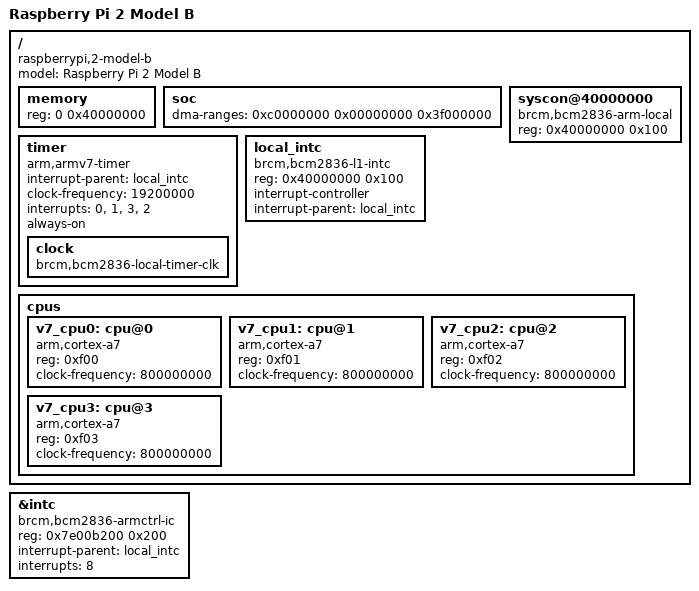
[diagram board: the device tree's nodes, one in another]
/dts-v1/;
#include "bcm2835-rpi.dtsi"

/ {
	compatible = "raspberrypi,2-model-b", "brcm,bcm2836";
	model = "Raspberry Pi 2 Model B";

	memory {
		reg = <0 0x40000000>;
	};

	soc {
		ranges = <0x7e000000 0x3f000000 0x1000000>,
			 <0x40000000 0x40000000 0x00001000>;
		dma-ranges = <0xc0000000 0x00000000 0x3f000000>;

		/delete-node/ timer@7e003000;
		/delete-node/ arm-pmu;
	};

	syscon@40000000 {
	       compatible = "brcm,bcm2836-arm-local", "syscon";
	       reg = <0x40000000 0x100>;
	};

	timer {
		interrupt-parent = <&local_intc>;
		compatible = "arm,armv7-timer";
		clock-frequency = <19200000>;
		interrupts = <0>, // PHYS_SECURE_PPI
			     <1>, // PHYS_NONSECURE_PPI
			     <3>, // VIRT_PPI
			     <2>; // HYP_PPI
		always-on;

		clock {
			compatible = "brcm,bcm2836-local-timer-clk";
		};
	};

	local_intc: local_intc {
		compatible = "brcm,bcm2836-l1-intc";
		reg = <0x40000000 0x100>;
		interrupt-controller;
		#interrupt-cells = <1>;
		interrupt-parent = <&local_intc>;
	};

	cpus: cpus {
		#address-cells = <1>;
		#size-cells = <0>;

		v7_cpu0: cpu@0 {
			device_type = "cpu";
			compatible = "arm,cortex-a7";
			reg = <0xf00>;
			clock-frequency = <800000000>;
		};

		v7_cpu1: cpu@1 {
			device_type = "cpu";
			compatible = "arm,cortex-a7";
			reg = <0xf01>;
			clock-frequency = <800000000>;
		};

		v7_cpu2: cpu@2 {
			device_type = "cpu";
			compatible = "arm,cortex-a7";
			reg = <0xf02>;
			clock-frequency = <800000000>;
		};

		v7_cpu3: cpu@3 {
			device_type = "cpu";
			compatible = "arm,cortex-a7";
			reg = <0xf03>;
			clock-frequency = <800000000>;
		};
	};
};

/* Make the BCM2835-style global interrupt controller be a child of the
 * CPU-local interrupt controller.
 */
&intc {
	compatible = "brcm,bcm2836-armctrl-ic";
	reg = <0x7e00b200 0x200>;
	interrupt-parent = <&local_intc>;
	interrupts = <8>;
};
